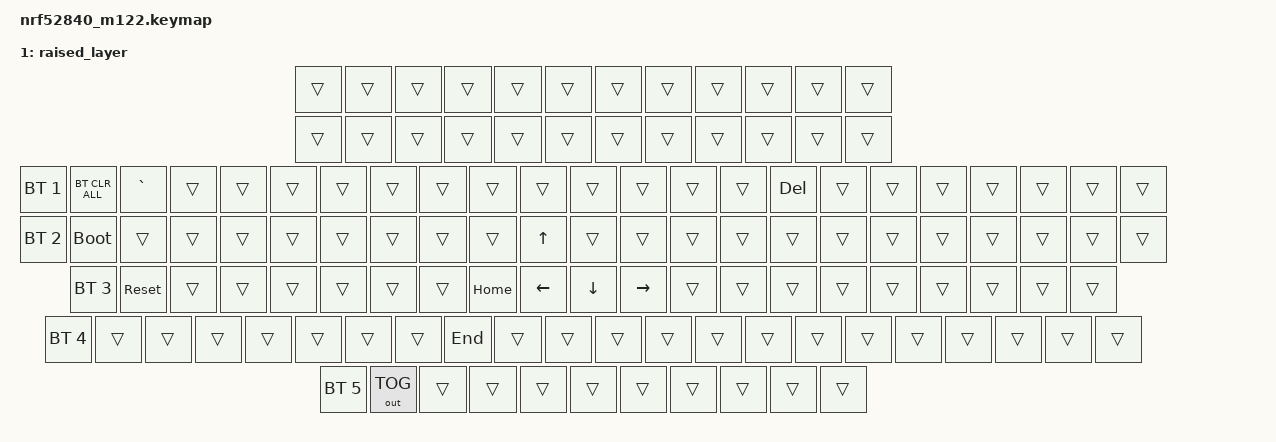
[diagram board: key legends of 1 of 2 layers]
/*
* Copyright (c) 2023 The ZMK Contributers
* SPDX-Licencse-Identifier: MIT
*/

#include <behaviors.dtsi>
#include <dt-bindings/zmk/keys.h>
#include <dt-bindings/zmk/bt.h>
#include <dt-bindings/zmk/outputs.h>
#define DEFAULT 0
#define RAISE 1
#define LOWER 2

/ {
    keymap {
        compatible = "zmk,keymap";

        default_layer { // Layer 0 - DEFAULT
            bindings = <

                &kp F13 &kp F14 &kp F15 &kp F16 &kp F17 &kp F18 &kp F19 &kp F20 &kp F21 &kp F22 &kp F23 &kp F24
                &kp F1  &kp F2  &kp F3  &kp F4  &kp F5  &kp F6  &kp F7  &kp F8  &kp F9  &kp F10 &kp F11 &kp F12
&trans &trans   &kp ESC &kp N1 &kp N2 &kp N3 &kp N4 &kp N5 &kp N6 &kp N7 &kp N8 &kp N9 &kp N0 &kp MINUS &kp EQUAL &kp BSPC    &kp INS  &kp HOME &kp PG_UP  &kp KP_NUM &kp KP_DIVIDE &kp KP_MULTIPLY &kp KP_MINUS
&trans &trans   &kp TAB &kp Q  &kp W  &kp E  &kp R  &kp T  &kp Y  &kp U  &kp I  &kp O  &kp P  &kp LBKT  &kp RBKT   &kp RET    &kp DEL  &kp END &kp PG_DN   &kp KP_N7  &kp KP_N8 &kp KP_N9  &kp KP_PLUS
&trans &trans   &kp LCTRL &kp A  &kp S  &kp D  &kp F  &kp G  &kp H  &kp J  &kp K  &kp L  &kp SEMI &kp SQT  &kp BSLH                     &kp UP              &kp KP_N4  &kp KP_N5 &kp KP_N6  &trans
&trans &trans   &kp LSHFT &trans &kp Z  &kp X  &kp C  &kp V  &kp B  &kp N  &kp M  &kp COMMA &kp DOT &kp FSLH     &kp RSHFT    &kp LEFT &kp DOWN &kp RIGHT  &kp KP_N1  &kp KP_N2 &kp KP_N3  &kp KP_ENTER
&trans &kp LGUI &mo RAISE           &kp LALT                    &kp SPACE                   &kp RALT             &kp RCTRL             &kp PSCRN           &kp KP_N0  &kp KP_N0 &kp KP_DOT 

            >;
        };

        raised_layer { // Layer 1 - RAISED
            bindings = <

                            &trans &trans &trans &trans &trans &trans &trans &trans &trans &trans &trans &trans
                            &trans &trans &trans &trans &trans &trans &trans &trans &trans &trans &trans &trans
&bt BT_SEL 1 &bt BT_CLR_ALL &kp GRAVE &trans &trans &trans &trans &trans &trans &trans &trans &trans &trans &trans &trans &kp DEL      &trans &trans &trans  &trans &trans &trans &trans
&bt BT_SEL 2 &bootloader    &trans &trans &trans &trans &trans &trans &trans &trans &kp UP &trans &trans &trans &trans    &trans       &trans &trans &trans  &trans &trans &trans &trans
&bt BT_SEL 3 &sys_reset     &trans &trans &trans &trans &trans &trans &kp HOME &kp LEFT &kp DOWN &kp RIGHT &trans &trans &trans &trans        &trans         &trans &trans &trans &trans
&bt BT_SEL 4 &trans         &trans &trans &trans &trans &trans &trans &kp END &trans &trans &trans &trans &trans        &trans         &trans &trans &trans  &trans &trans &trans &trans
&bt BT_SEL 5 &out OUT_TOG   &trans        &trans                      &trans                              &trans        &trans                &trans         &trans &trans &trans

            >;
        };
    };
};

// Blank layout
//               &trans &trans &trans &trans &trans &trans &trans &trans &trans &trans &trans &trans
//               &trans &trans &trans &trans &trans &trans &trans &trans &trans &trans &trans &trans
// &trans &trans &trans &trans &trans &trans &trans &trans &trans &trans &trans &trans &trans &trans &trans &trans  &trans &trans &trans  &trans &trans &trans &trans
// &trans &trans &trans &trans &trans &trans &trans &trans &trans &trans &trans &trans &trans &trans &trans &trans  &trans &trans &trans  &trans &trans &trans &trans
// &trans &trans &trans &trans &trans &trans &trans &trans &trans &trans &trans &trans &trans &trans &trans &trans         &trans         &trans &trans &trans &trans
// &trans &trans &trans &trans &trans &trans &trans &trans &trans &trans &trans &trans &trans &trans        &trans  &trans &trans &trans  &trans &trans &trans &trans
// &trans &trans &trans        &trans                      &trans                             &trans        &trans         &trans         &trans &trans &trans 
//
